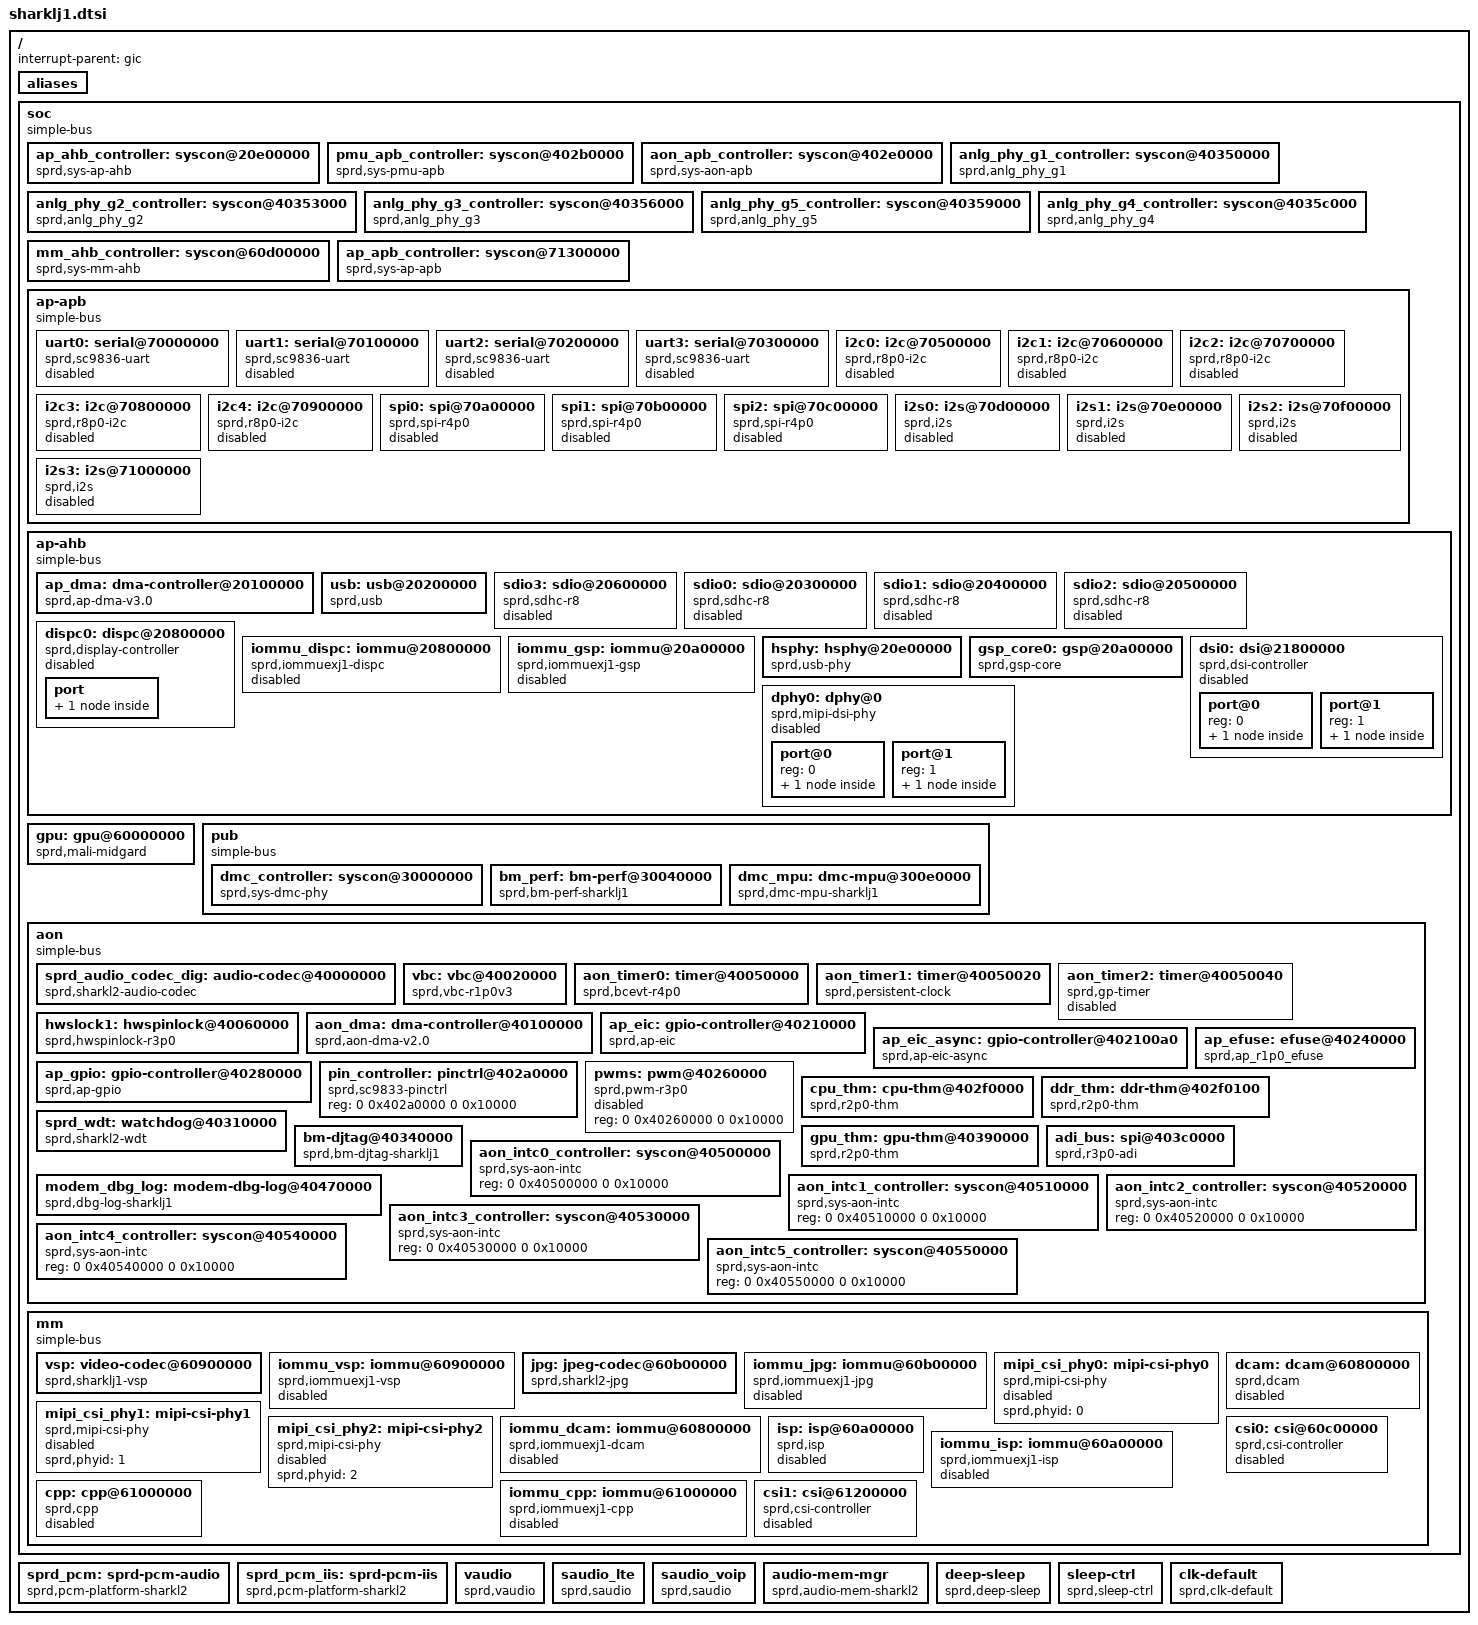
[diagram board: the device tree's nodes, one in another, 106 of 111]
/*
 * Spreadtrum Sharklj1 platform DTS file
 *
 * Copyright (C) 2016, Spreadtrum Communications Inc.
 *
 * This file is licensed under a dual GPLv2 or X11 license.
 */

#include <dt-bindings/interrupt-controller/arm-gic.h>

/ {
	interrupt-parent = <&gic>;
	#address-cells = <2>;
	#size-cells = <2>;

	aliases {
		serial0 = &uart0;
		serial1 = &uart1;
		serial2 = &uart2;
		serial3 = &uart3;
		i2c0 = &i2c0;
		i2c1 = &i2c1;
		i2c2 = &i2c2;
		i2c3 = &i2c3;
		i2c4 = &i2c4;
		spi0 = &spi0;
		spi1 = &spi1;
		spi2 = &spi2;
		hwspinlock1 = &hwslock1;
		thm-sensor0 = &cpu_thm;
		thm-sensor1 = &ddr_thm;
		thm-sensor2 = &gpu_thm;
	};

	soc: soc {
		compatible = "simple-bus";
		#address-cells = <2>;
		#size-cells = <2>;
		ranges;

		ap_ahb_controller: syscon@20e00000 {
			compatible = "sprd,sys-ap-ahb", "syscon";
			reg = <0 0x20e00000 0 0x100000>;
			hwlocks = <&hwslock1 1>;
			hwlock-names = "syscon";
		};

		pmu_apb_controller: syscon@402b0000 {
			compatible = "sprd,sys-pmu-apb", "syscon";
			reg = <0 0x402b0000 0 0x10000>;
			hwlocks = <&hwslock1 1>;
			hwlock-names = "syscon";
		};

		aon_apb_controller: syscon@402e0000 {
			compatible = "sprd,sys-aon-apb", "syscon";
			reg = <0 0x402e0000 0 0x10000>;
			hwlocks = <&hwslock1 1>;
			hwlock-names = "syscon";
		};

		anlg_phy_g1_controller: syscon@40350000 {
			compatible = "sprd,anlg_phy_g1", "syscon";
			reg = <0 0x40350000 0 0x3000>;
			hwlocks = <&hwslock1 1>;
			hwlock-names = "syscon";
		};

		anlg_phy_g2_controller: syscon@40353000 {
			compatible = "sprd,anlg_phy_g2", "syscon";
			reg = <0 0x40353000 0 0x3000>;
			hwlocks = <&hwslock1 1>;
			hwlock-names = "syscon";
		};

		anlg_phy_g3_controller: syscon@40356000 {
			compatible = "sprd,anlg_phy_g3", "syscon";
			reg = <0 0x40356000 0 0x3000>;
			hwlocks = <&hwslock1 1>;
			hwlock-names = "syscon";
		};

		anlg_phy_g5_controller: syscon@40359000 {
			compatible = "sprd,anlg_phy_g5", "syscon";
			reg = <0 0x40359000 0 0x3000>;
			hwlocks = <&hwslock1 1>;
			hwlock-names = "syscon";
		};

		anlg_phy_g4_controller: syscon@4035c000 {
			compatible = "sprd,anlg_phy_g4", "syscon";
			reg = <0 0x4035c000 0 0x3000>;
			hwlocks = <&hwslock1 1>;
			hwlock-names = "syscon";
		};

		mm_ahb_controller: syscon@60d00000 {
			compatible = "sprd,sys-mm-ahb", "syscon";
			reg = <0 0x60d00000 0 0x100000>;
			hwlocks = <&hwslock1 1>;
			hwlock-names = "syscon";
		};

		ap_apb_controller: syscon@71300000 {
			compatible = "sprd,sys-ap-apb", "syscon";
			reg = <0 0x71300000 0 0x100000>;
			hwlocks = <&hwslock1 1>;
			hwlock-names = "syscon";
		};

		ap-apb {
			compatible = "simple-bus";
			#address-cells = <2>;
			#size-cells = <2>;
			ranges;

			uart0: serial@70000000 {
				compatible = "sprd,sc9836-uart",
					     "sprd,sc9838-uart";
				reg = <0 0x70000000 0 0x100>;
				interrupts = <GIC_SPI 2 IRQ_TYPE_LEVEL_HIGH>;
				clock-names = "uart", "source","enable";
				status = "disabled";
			};

			uart1: serial@70100000 {
				compatible = "sprd,sc9836-uart",
					     "sprd,sc9838-uart";
				reg = <0 0x70100000 0 0x100>;
				interrupts = <GIC_SPI 3 IRQ_TYPE_LEVEL_HIGH>;
				clock-names = "uart", "source","enable";
				status = "disabled";
			};

			uart2: serial@70200000 {
				compatible = "sprd,sc9836-uart",
					     "sprd,sc9838-uart";
				reg = <0 0x70200000 0 0x100>;
				interrupts = <GIC_SPI 4 IRQ_TYPE_LEVEL_HIGH>;
				clock-names = "uart", "source","enable";
				status = "disabled";
			};

			uart3: serial@70300000 {
				compatible = "sprd,sc9836-uart",
					     "sprd,sc9838-uart";
				reg = <0 0x70300000 0 0x100>;
				interrupts = <GIC_SPI 5 IRQ_TYPE_LEVEL_HIGH>;
				clock-names = "uart", "source","enable";
				status = "disabled";
			};

			i2c0: i2c@70500000 {
				compatible = "sprd,r8p0-i2c";
				reg = <0 0x70500000 0 0x1000>;
				interrupts = <GIC_SPI 11 IRQ_TYPE_LEVEL_HIGH>;
				clock-names = "i2c", "source","enable";
				clock-frequency = <100000>;
				#address-cells = <1>;
				#size-cells = <0>;
				status = "disabled";
			};

			i2c1: i2c@70600000 {
				compatible = "sprd,r8p0-i2c";
				reg = <0 0x70600000 0 0x1000>;
				interrupts = <GIC_SPI 12 IRQ_TYPE_LEVEL_HIGH>;
				clock-names = "i2c", "source","enable";
				clock-frequency = <100000>;
				#address-cells = <1>;
				#size-cells = <0>;
				status = "disabled";
			};

			i2c2: i2c@70700000 {
				compatible = "sprd,r8p0-i2c";
				reg = <0 0x70700000 0 0x1000>;
				interrupts = <GIC_SPI 13 IRQ_TYPE_LEVEL_HIGH>;
				clock-names = "i2c", "source","enable";
				clock-frequency = <100000>;
				#address-cells = <1>;
				#size-cells = <0>;
				status = "disabled";
			};

			i2c3: i2c@70800000 {
				compatible = "sprd,r8p0-i2c";
				reg = <0 0x70800000 0 0x1000>;
				interrupts = <GIC_SPI 14 IRQ_TYPE_LEVEL_HIGH>;
				clock-names = "i2c", "source","enable";
				clock-frequency = <400000>;
				#address-cells = <1>;
				#size-cells = <0>;
				status = "disabled";
			};

			i2c4: i2c@70900000 {
				compatible = "sprd,r8p0-i2c";
				reg = <0 0x70900000 0 0x1000>;
				interrupts = <GIC_SPI 15 IRQ_TYPE_LEVEL_HIGH>;
				clock-names = "i2c", "source","enable";
				clock-frequency = <100000>;
				#address-cells = <1>;
				#size-cells = <0>;
				status = "disabled";
			};

			spi0: spi@70a00000{
				compatible = "sprd,spi-r4p0";
				reg = <0 0x70a00000 0 0x1000>;
				interrupts = <GIC_SPI 7 IRQ_TYPE_LEVEL_HIGH>;
				clock-names = "spi", "source","enable";
				sprd,dma-mode = <0>;
				sprd,rxtx-dma = <11 12>;
				dma-names = "rx_chn", "tx_chn";
				dmas = <&ap_dma 11 &ap_dma 12>;
				#address-cells = <1>;
				#size-cells = <0>;
				status = "disabled";
			};

			spi1: spi@70b00000{
				compatible = "sprd,spi-r4p0";
				reg = <0 0x70b00000 0 0x1000>;
				interrupts = <GIC_SPI 8 IRQ_TYPE_LEVEL_HIGH>;
				clock-names = "spi", "source", "enable";
				sprd,dma-mode = <0>;
				sprd,rxtx-dma = <13 14>;
				dma-names = "rx_chn", "tx_chn";
				dmas = <&ap_dma 13 &ap_dma 14>;
				#address-cells = <1>;
				#size-cells = <0>;
				status = "disabled";
			};

			spi2: spi@70c00000{
				compatible = "sprd,spi-r4p0";
				reg = <0 0x70c00000 0 0x1000>;
				interrupts = <GIC_SPI 9 IRQ_TYPE_LEVEL_HIGH>;
				clock-names = "spi", "source","enable";
				sprd,dma-mode = <0>;
				sprd,rxtx-dma = <15 16>;
				dma-names = "rx_chn", "tx_chn";
				dmas = <&ap_dma 15 &ap_dma 16>;
				#address-cells = <1>;
				#size-cells = <0>;
				status = "disabled";
			};

			i2s0: i2s@70d00000 {
				compatible = "sprd,i2s";
				reg = <0 0x70d00000 0 0x100000>;
				sprd,dai_name = "i2s_bt_sco0";
				sprd,hw_port = <0>;
				sprd,syscon-ap-apb = <&ap_apb_controller>;
				#sound-dai-cells = <0>;
				status = "disable";
			};

			i2s1: i2s@70e00000 {
				compatible = "sprd,i2s";
				reg = <0 0x70e00000 0 0x100000>;
				sprd,dai_name = "i2s_bt_sco1";
				sprd,hw_port = <1>;
				sprd,syscon-ap-apb = <&ap_apb_controller>;
				#sound-dai-cells = <0>;
				status = "disable";
			};

			i2s2: i2s@70f00000 {
				compatible = "sprd,i2s";
				reg = <0 0x70f00000 0 0x100000>;
				sprd,dai_name = "i2s_bt_sco2";
				sprd,hw_port = <2>;
				sprd,syscon-ap-apb = <&ap_apb_controller>;
				#sound-dai-cells = <0>;
				status = "disable";
			};

			i2s3: i2s@71000000 {
				compatible = "sprd,i2s";
				reg = <0 0x71000000 0 0x100000>;
				sprd,dai_name = "i2s_bt_sco3";
				sprd,hw_port = <3>;
				sprd,syscon-ap-apb = <&ap_apb_controller>;
				#sound-dai-cells = <0>;
				status = "disable";
			};
		};

		ap-ahb {
			compatible = "simple-bus";
			#address-cells = <2>;
			#size-cells = <2>;
			ranges;

			ap_dma: dma-controller@20100000 {
				compatible = "sprd,ap-dma-v3.0";
				reg = <0 0x20100000 0 0x4000>;
				interrupts = <GIC_SPI 50 IRQ_TYPE_LEVEL_HIGH>;
				#dma-cells = <1>;
				#dma-channels = <28>;
				sprd,full-type-offset = <0>;
				sprd,syscon-dma-glb = <&ap_ahb_controller>;
				clock-names = "enable";
				clocks = <&clk_ap_ahb_gates 5>;
			};

			usb: usb@20200000 {
				compatible  = "sprd,usb";
				reg = <0 0x20200000 0 0x2000>;
				interrupts = <GIC_SPI 55 IRQ_TYPE_LEVEL_HIGH>;
				interrupt-names = "mc";
				clocks = <&clk_ap_ahb_gates 4>;
				clock-names = "core_clk";
				phy-type = "usb20_sprd_phy";
				usb-phy = <&hsphy>;
				phy-names = "usb";
				dr-mode = "peripheral";
			};

			sdio3: sdio@20600000 {
				compatible  = "sprd,sdhc-r8";
				reg = <0 0x20600000 0 0x1000>;
				interrupts = <GIC_SPI 60 IRQ_TYPE_LEVEL_HIGH>;
				clock-names = "sdio","source","enable",
					"ckg_eb","ckg_1x_eb";
				clocks = <&clk_emmc_2x>,<&clk_rpll_390m>,
					<&clk_ap_ahb_gates 11>,
					<&clk_aon_eb0_gates 1>,
					<&clk_aon_eb0_gates 0>;
				status = "disabled";
			};

			sdio0: sdio@20300000 {
				compatible  = "sprd,sdhc-r8";
				reg = <0 0x20300000 0 0x1000>;
				interrupts = <GIC_SPI 57 IRQ_TYPE_LEVEL_HIGH>;
				clock-names = "sdio","source","enable",
					"ckg_eb","ckg_1x_eb";
				clocks = <&clk_sdio0_2x>,<&clk_rpll_390m>,
					<&clk_ap_ahb_gates 8>,
					<&clk_aon_eb0_gates 3>,
					<&clk_aon_eb0_gates 2>;
				status = "disabled";
			};

			sdio1: sdio@20400000 {
				compatible  = "sprd,sdhc-r8";
				reg = <0 0x20400000 0 0x1000>;
				interrupts = <GIC_SPI 58 IRQ_TYPE_LEVEL_HIGH>;
				clock-names = "sdio", "source","enable",
					"ckg_eb","ckg_1x_eb";
				clocks = <&clk_sdio1_2x>,<&clk_rpll_390m>,
					<&clk_ap_ahb_gates 9>,
					<&clk_aon_eb0_gates 5>,
					<&clk_aon_eb0_gates 4>;
				status = "disabled";
			};

			sdio2: sdio@20500000 {
				compatible  = "sprd,sdhc-r8";
				reg = <0 0x20500000 0 0x1000>;
				interrupts = <GIC_SPI 59 IRQ_TYPE_LEVEL_HIGH>;
				clock-names = "sdio","source","enable",
					"ckg_eb","ckg_1x_eb";
				clocks = <&clk_sdio2_2x>,<&clk_rpll_390m>,
					<&clk_ap_ahb_gates 10>,
					<&clk_aon_eb0_gates 7>,
					<&clk_aon_eb0_gates 6>;
				status = "disabled";
			};


			dispc0: dispc@20800000 {
				compatible = "sprd,display-controller";
				reg = <0x0 0x20800000 0x0 0x1000>;
				dev-id = <0>;
				sprd,dpi_clk_div = <1>;
				interrupts = <GIC_SPI 46 IRQ_TYPE_LEVEL_HIGH>;
				clock-src = <384000000 128000000>;
				clock-names =   "clk_dispc_core_parent",
						"clk_dispc_dpi_parent",
						"clk_dispc_core",
						"clk_dispc_dpi",
						"clk_dispc_ahb_eb";

				clocks =	<&clk_twpll_384m>,
						<&clk_twpll_128m>,
						<&clk_dispc0>,
						<&clk_dispc0_dpi>,
						<&clk_ap_ahb_gates 1>;
				iommus = <&iommu_dispc>;
				status = "disabled";

				sprd,ip = "dispc-lite-r2p0";
				sprd,soc = "sharklj1";

				/* output port */
				port {
					dispc0_out: endpoint@0 {
						remote-endpoint = <&dsi0_in>;
					};
				};
			};

			iommu_dispc: iommu@20800000 {
				compatible = "sprd,iommuexj1-dispc";
				reg = <0x0 0x20800000 0x0 0x800>,
					<0x0 0x20800800 0x0 0x60>,
					<0x0 0x30000000 0x0 0x8000000>;
				reg_name = "mmu_interrupt_reg","mmu_reg",
						"iova pool";
				status = "disabled";
				#iommu-cells = <0>;
			};

			iommu_gsp: iommu@20a00000 {
				compatible = "sprd,iommuexj1-gsp";
				reg = <0x0 0x20a00000 0x0 0x804>,
					<0x0 0x20a00804 0x0 0x60>,
					<0x0 0x20000000 0x0 0x10000000>;
				reg_name = "mmu_interrupt_reg","mmu_reg",
						"iova pool";
				status = "disabled";
				#iommu-cells = <0>;
			};

			hsphy: hsphy@20e00000 {
				compatible = "sprd,usb-phy";
				sprd,syscon-enable = <&aon_apb_controller>;
				sprd,syscon-apahb = <&ap_ahb_controller>;
				sprd,syscon-anag2 = <&anlg_phy_g2_controller>;
				sprd,tune-value = <0x0c373b9d>;
				sprd,vdd-voltage = <3300000>;
				#phy-cells = <0>;
			};

			gsp_core0: gsp@20a00000 {
				compatible = "sprd,gsp-core";
				reg = <0 0x20a00000  0 0x1000>;
				core-id = <0>;
				kcfg-num = <8>;
				interrupts = <GIC_SPI 51 IRQ_TYPE_LEVEL_HIGH>;
				iommus = <&iommu_gsp>;
				sprd,sys-ap-ahb = <&ap_ahb_controller>;
				clock-names = "clk_gsp",
						 "clk_gsp_parent",
						 "clk_gsp_eb";
				clocks = <&clk_gsp>,
						 <&clk_twpll_307m2>,
						 <&clk_ap_ahb_gates 3>;
			};

			dsi0: dsi@21800000 {
				compatible = "sprd,dsi-controller";
				#address-cells = <1>;
				#size-cells = <0>;
				dev-id = <0>;
				reg = <0x0 0x21800000 0x0 0x1000>;
				interrupts = <GIC_SPI 48 IRQ_TYPE_LEVEL_HIGH>,
					<GIC_SPI 49 IRQ_TYPE_LEVEL_HIGH>;
				clock-names =   "clk_dsi0_ahb_eb";
				clocks = <&clk_ap_ahb_gates 0>;
				status = "disabled";

				sprd,ip = "sprd,dsi-ctrl-r1p0";
				sprd,soc = "sharklj1";

				/* output port */
				port@0 {
					reg = <0>;
					dsi0_out: endpoint {
						remote-endpoint = <&dphy0_in>;
					};
				};

				/* input port */
				port@1 {
					reg = <1>;
					dsi0_in: endpoint {
						remote-endpoint = <&dispc0_out>;
					};
				};
			};

			dphy0: dphy@0 {
				compatible = "sprd,mipi-dsi-phy";
				#address-cells = <1>;
				#size-cells = <0>;
				reg = <0x0 0x21800000 0x0 0x1000>;
				status = "disabled";

				sprd,ip = "sprd,megacores-sharkle";
				sprd,soc = "sharklj1";

				/* output port */
				port@0 {
					reg = <0>;
					dphy0_out: endpoint {
						remote-endpoint = <&panel_in>;
					};
				};

				/* input port*/
				port@1 {
					reg = <1>;
					dphy0_in: endpoint {
						remote-endpoint = <&dsi0_out>;
					};
				};
			};
		};

		gpu: gpu@60000000 {
			compatible = "sprd,mali-midgard";
			reg = <0 0x60000000 0 0x4000>;
			sprd,syscon-aon-apb = <&aon_apb_controller>;
			sprd,syscon-pmu-apb = <&pmu_apb_controller>;
			interrupts = <GIC_SPI 39 IRQ_TYPE_LEVEL_HIGH>,
				<GIC_SPI 39 IRQ_TYPE_LEVEL_HIGH>,
				<GIC_SPI 39 IRQ_TYPE_LEVEL_HIGH>;
			interrupt-names = "JOB",
				"MMU",
				"GPU";

			system-coherency = <31>;

			clocks = <&clk_aon_apb_gates0 27>,<&clk_gpu>,
				<&clk_twpll_153m6>,<&clk_twpll_192m>,
				<&clk_twpll_256m>,<&clk_twpll_307m2>,
				<&clk_twpll_384m>,<&clk_twpll_512m>,
				<&clk_gpll>;

			operating-points = <
				/* kHz    uV */
				153600    0
				256000    0
				384000    0
				512000    0
				700000    0
				>;

			sprd,dfs-lists = <
				/* kHz  uV idx div */
				153600  0   2   1
				256000  0   4   1
				384000  0   6   1
				512000  0   7   1
				700000  0   8   1
				>;

			sprd,dfs-default = <1>;
			sprd,dfs-scene-extreme = <3>;
			sprd,dfs-scene-high = <2>;
			sprd,dfs-scene-medium = <1>;
			sprd,dfs-scene-low = <0>;
			sprd,dfs-range-max = <4>;
			sprd,dfs-range-min = <0>;
		};

		pub {
			compatible = "simple-bus";
			#address-cells = <2>;
			#size-cells = <2>;
			ranges;

			dmc_controller: syscon@30000000 {
				compatible = "sprd,sys-dmc-phy", "syscon";
				reg = <0 0x30000000 0 0x400>;
				sprd,sizel_off = <0x1b4>;
				sprd,sizeh_off = <0x1b8>;
			};

			bm_perf: bm-perf@30040000{
				compatible = "sprd,bm-perf-sharklj1";
				reg = <0 0x30040000 0 0x80000>,
					<0 0 0 0>,
					<0 0x40270000 0 0x10000>,
					<0 0x300e0000 0 0x4>,
					<0 0 0 0>;
				interrupts = <GIC_SPI 86 IRQ_TYPE_LEVEL_HIGH>;
				reg-names = "pub0","pub1","timer",
						"pub0_glb","pub1_glb";
				sprd,syscon-aon-glb = <&aon_apb_controller>;
			};

			dmc_mpu: dmc-mpu@300e0000{
				compatible = "sprd,dmc-mpu-sharklj1";
				reg = <0 0x300e0000 0 0x4000>;
				interrupts = <GIC_SPI 61 IRQ_TYPE_LEVEL_HIGH>;
			};
		};

		aon {
			compatible = "simple-bus";
			#address-cells = <2>;
			#size-cells = <2>;
			ranges;

			sprd_audio_codec_dig: audio-codec@40000000 {
				compatible = "sprd,sharkl2-audio-codec";
				reg = <0 0x40000000 0 0x2000>;
				sprd,def_da_fs = <44100>;
				interrupts = <GIC_SPI 20  IRQ_TYPE_NONE>;
				sprd,syscon-aon-apb = <&aon_apb_controller>;
				/* sharklj1 use g1 */
				sprd,anlg-phy-g-syscon = <&anlg_phy_g1_controller>;
			};

			vbc: vbc@40020000 {
				compatible = "sprd,vbc-r1p0v3";
				#sound-dai-cells = <1>;
				reg = <0 0x40020000 0 0x10000>;
				sprd,clk-stable = <0x402d0060 0x4>;
				sprd,syscon-aon-apb = <&aon_apb_controller>;
				sprd,syscon-pmu-apb = <&pmu_apb_controller>;
				sprd,dynamic-eq-support = <0>;
				/* da01, ad01, ad23 */
				sprd,vbc-iis-lr-invert = <0 0 1>;
				/*
				 * 0: aon dma, 1: ap dma
				 * da01, da23, ad01, ad23
				 */
				sprd,vbc-use-dma-type = <0 0 1 1>;
				sprd,vbc-use-ad01-only = <0>;
				/* iis pin map */
				pinctrl-names =
				/* iis 0 */
				"ap_iis0_0", "pubcp_iis0_0", "tgdsp_iis0_0",
				"vbc_iis1_0", "vbc_iis2_0", "vbc_iis3_0",
				/* iis 2 */
				"ap_iis0_2", "pubcp_iis0_2", "tgdsp_iis0_2",
				"vbc_iis1_2", "vbc_iis2_2", "vbc_iis3_2";

				/* sys iis 0 */
				pinctrl-0 = <&ap_iis0_0>;
				pinctrl-1 = <&pubcp_iis0_0>;
				pinctrl-2 = <&tgdsp_iis0_0>;
				pinctrl-3 = <&vbc_iis1_0>;
				pinctrl-4 = <&vbc_iis2_0>;
				pinctrl-5 = <&vbc_iis3_0>;
				/* sys iis 2 */
				pinctrl-6 = <&ap_iis0_2>;
				pinctrl-7 = <&pubcp_iis0_2>;
				pinctrl-8 = <&tgdsp_iis0_2>;
				pinctrl-9 = <&vbc_iis1_2>;
				pinctrl-10 = <&vbc_iis2_2>;
				pinctrl-11 = <&vbc_iis3_2>;
			};

			aon_timer0: timer@40050000 {
				compatible = "sprd,bcevt-r4p0";
				reg = <0 0x40050000 0 0x14>;
				interrupts = <GIC_SPI 28 IRQ_TYPE_LEVEL_HIGH>;
				clock-frequency = <32768>;
			};

			aon_timer1: timer@40050020 {
				compatible = "sprd,persistent-clock";
				reg = <0 0x40050020 0 0x14>;
				interrupts = <GIC_SPI 28 IRQ_TYPE_LEVEL_HIGH>;
				clock-frequency = <32768>;
			};

			aon_timer2: timer@40050040 {
				compatible = "sprd,gp-timer";
				reg = <0 0x40050040 0 0x14>;
				clock-frequency = <26000000>;
				status = "disabled";
			};

			hwslock1: hwspinlock@40060000{
				compatible  = "sprd,hwspinlock-r3p0";
				reg = <0 0x40060000 0 0x1000>;
				#hwlock-cells = <1>;
				hwlocks-base = <0>;
				hwlocks-num = <32>;
				clock-names = "enable";
				sprd,axi-id;
			};

			aon_dma: dma-controller@40100000 {
				compatible = "sprd,aon-dma-v2.0";
				reg = <0x0 0x40100000 0x0 0x4000>;
				#dma-cells = <1>;
				#dma-channels = <12>;
				sprd,full-type-offset = <0>;
				sprd,syscon-dma-glb = <&aon_apb_controller>;
				clock-names = "enable";
				clocks = <&clk_aon_apb_gates1 22>;
			};

			ap_eic: gpio-controller@40210000 {
				compatible = "sprd,ap-eic";
				reg =	<0x0 0x40210000 0x0 0x80>,
					<0x0 0x40370000 0x0 0x80>;
				gpio-controller;
				#gpio-cells = <2>;
				sprd,gpiobase = <288>;
				sprd,ngpios = <32>;
				interrupt-controller;
				#interrupt-cells = <2>;
				interrupts = <GIC_SPI 37 IRQ_TYPE_LEVEL_HIGH>;
			};

			ap_eic_async: gpio-controller@402100a0 {
				compatible = "sprd,ap-eic-async";
				reg =	<0x0 0x402100a0 0x0 0x40>,
					<0x0 0x403700a0 0x0 0x40>;
				gpio-controller;
				#gpio-cells = <2>;
				sprd,gpiobase = <336>;
				sprd,ngpios = <32>;
				interrupt-controller;
				#interrupt-cells = <2>;
				interrupts = <GIC_SPI 37 IRQ_TYPE_LEVEL_HIGH>;
			};

			ap_efuse: efuse@40240000 {
				compatible = "sprd,ap_r1p0_efuse";
				sprd,syscon-enable = <&aon_apb_controller>;
				reg = <0 0x40240000 0 0x1000>;
				clock-names = "enable";
				clocks = <&clk_aon_apb_gates0 13>;
				sprd,block-num = <16>;
				sprd,block-width = <32>;
				hwlocks = <&hwslock1 8>;
				hwlock-names = "ap_efuse";
			};

			ap_gpio: gpio-controller@40280000 {
				compatible = "sprd,ap-gpio";
				reg = <0x0 0x40280000 0x0 0x1000>;
				gpio-controller;
				#gpio-cells = <2>;
				sprd,gpiobase = <0>;
				sprd,ngpios = <256>;
				interrupt-controller;
				#interrupt-cells = <2>;
				interrupts = <GIC_SPI 35 IRQ_TYPE_LEVEL_HIGH>;
			};

			pin_controller: pinctrl@402a0000 {
				compatible = "sprd,sc9833-pinctrl";
				reg = <0 0x402a0000 0 0x10000>;
			};

			pwms: pwm@40260000 {
				#pwm-cells = <2>;
				compatible = "sprd,pwm-r3p0";
				reg = <0 0x40260000 0 0x10000>;
				status = "disabled";
			};

			cpu_thm: cpu-thm@402f0000 {
				compatible = "sprd,r2p0-thm";
				sprd,syscon-enable = <&aon_apb_controller>;
				reg = <0 0x402f0000 0 0x100>;
				clock-names = "enable";
				clocks = <&clk_aon_apb_gates1 1>;
				#thermal-sensor-cells = <1>;
				power-down = <0>;
				otp-temp = <120000>;
				algor_ver = <1>;
				cal_k = <903>;
				cal_b = <71290>;
				cal_efuse_blk = <8>;
				cal_efuse_bit = <9>;
				ratio_off_bit = <2>;
				ratio_sign_bit = <1>;
			};

			ddr_thm: ddr-thm@402f0100 {
				compatible = "sprd,r2p0-thm";
				sprd,syscon-enable = <&aon_apb_controller>;
				reg = <0 0x402f0100 0 0x100>;
				clock-names = "enable";
				clocks = <&clk_aon_apb_gates1 1>;
				#thermal-sensor-cells = <1>;
				power-down = <0>;
				otp-temp = <120000>;
				algor_ver = <1>;
				cal_k = <903>;
				cal_b = <71290>;
				cal_efuse_blk = <8>;
				cal_efuse_bit = <24>;
				ratio_off_bit = <17>;
				ratio_sign_bit = <16>;
			};

			sprd_wdt: watchdog@40310000 {
				compatible = "sprd,sharkl2-wdt";
				reg = <0 0x40310000 0 0x1000>;
				interrupts = <GIC_SPI 124 IRQ_TYPE_LEVEL_HIGH>;
				clock-names = "enable", "rtc_enable";
				sprd,wdt-enable = <&aon_apb_controller>;
			};

			bm-djtag@40340000 {
				compatible = "sprd,bm-djtag-sharklj1";
				reg = <0 0x40340000 0 0x10000>;
				interrupts = <GIC_SPI 67 IRQ_TYPE_LEVEL_HIGH>;
				sprd,syscon-aon-glb = <&aon_apb_controller>;
				sprd,syscon-ap-glb = <&ap_ahb_controller>;
				hwlocks = <&hwslock1 10>;
				hwlock-names = "djtag";
			};

			gpu_thm: gpu-thm@40390000 {
				compatible = "sprd,r2p0-thm";
				sprd,syscon-enable = <&aon_apb_controller>;
				reg = <0 0x40390000 0 0x100>;
				clock-names = "enable";
				clocks = <&clk_aon_apb_gates1 1>;
				#thermal-sensor-cells = <1>;
				power-down = <0>;
				otp-temp = <120000>;
				algor_ver = <1>;
				cal_k = <903>;
				cal_b = <71290>;
				cal_efuse_blk = <9>;
				cal_efuse_bit = <9>;
				ratio_off_bit = <2>;
				ratio_sign_bit = <1>;
			};

			adi_bus: spi@403c0000 {
				compatible = "sprd,r3p0-adi";
				reg = <0 0x403c0000 0 0x10000>;
				#address-cells = <1>;
				#size-cells = <0>;
				sprd,hw-channels = <33 0x8c20>;
			};

			modem_dbg_log: modem-dbg-log@40470000 {
				compatible = "sprd,dbg-log-sharklj1";
				reg = <0 0x40470000 0 0x1000>,
				<0 0x404a0000 0 0x1000>;
				sprd,syscon-aon-apb = <&aon_apb_controller>;
			};

			aon_intc0_controller: syscon@40500000 {
				compatible = "sprd,sys-aon-intc", "syscon";
				reg = <0 0x40500000 0 0x10000>;
			};

			aon_intc1_controller: syscon@40510000 {
				compatible = "sprd,sys-aon-intc", "syscon";
				reg = <0 0x40510000 0 0x10000>;
			};

			aon_intc2_controller: syscon@40520000 {
				compatible = "sprd,sys-aon-intc", "syscon";
				reg = <0 0x40520000 0 0x10000>;
			};

			aon_intc3_controller: syscon@40530000 {
				compatible = "sprd,sys-aon-intc", "syscon";
				reg = <0 0x40530000 0 0x10000>;
			};

			aon_intc4_controller: syscon@40540000 {
				compatible = "sprd,sys-aon-intc", "syscon";
				reg = <0 0x40540000 0 0x10000>;
			};

			aon_intc5_controller: syscon@40550000 {
				compatible = "sprd,sys-aon-intc", "syscon";
				reg = <0 0x40550000 0 0x10000>;
			};
		};

		mm {
			compatible = "simple-bus";
			#address-cells = <2>;
			#size-cells = <2>;
			ranges;

			vsp: video-codec@60900000{
				compatible = "sprd,sharklj1-vsp";
				reg = <0 0x60900000 0 0xc000>;
				interrupts = <GIC_SPI 43 IRQ_TYPE_LEVEL_HIGH>;
				sprd,syscon-pmu-apb = <&pmu_apb_controller>;
				sprd,syscon-aon-apb = <&aon_apb_controller>;
				sprd,syscon-mm-ahb = <&mm_ahb_controller>;
				iommus = <&iommu_vsp>;
				status = "ok";
			};

			iommu_vsp: iommu@60900000 {
				compatible = "sprd,iommuexj1-vsp";
				reg = <0 0x60900000 0 0x1140>,
				<0 0x60901140 0 0x60>,
				<0 0x10000000 0 0x10000000>;
				reg_name = "mmu_interrupt_reg","mmu_reg",
						"iova pool";
				status = "disabled";
				#iommu-cells = <0>;
			};


			jpg: jpeg-codec@60b00000{
				compatible = "sprd,sharkl2-jpg";
				reg = <0 0x60b00000 0 0x8000>;
				interrupts = <GIC_SPI 42 IRQ_TYPE_LEVEL_HIGH>;
				sprd,syscon-pmu-apb = <&pmu_apb_controller>;
				sprd,syscon-aon-apb = <&aon_apb_controller>;
				sprd,syscon-mm-ahb = <&mm_ahb_controller>;
				iommus = <&iommu_jpg>;
				status = "okay";
			};

			iommu_jpg: iommu@60b00000 {
				compatible = "sprd,iommuexj1-jpg";
				reg = <0 0x60b00000 0 0x100>,
				<0 0x60b00100 0 0x400>,
				<0 0x70000000 0 0x10000000>;
				reg_name = "mmu_interrupt_reg","mmu_reg",
						"iova pool";
				status = "disabled";
				#iommu-cells = <0>;
			};

			mipi_csi_phy0: mipi-csi-phy0 {
				compatible = "sprd,mipi-csi-phy";
				sprd,phyid = <0>;
				status = "disabled";
			};

			mipi_csi_phy1: mipi-csi-phy1 {
				compatible = "sprd,mipi-csi-phy";
				sprd,phyid = <1>;
				status = "disabled";
			};

			mipi_csi_phy2: mipi-csi-phy2 {
				compatible = "sprd,mipi-csi-phy";
				sprd,phyid = <2>;
				status = "disabled";
			};

			dcam: dcam@60800000 {
				compatible = "sprd,dcam";
				reg = <0 0x60800000 0 0x1000>;
				interrupts = <GIC_SPI 45 IRQ_TYPE_LEVEL_HIGH>;
				sprd,cam-ahb-syscon = <&mm_ahb_controller>;
				sprd,aon-apb-syscon = <&aon_apb_controller>;
				sprd,syscon-pmu-apb = <&pmu_apb_controller>;
				sprd,isp = <&isp>;
				sprd,dcam-count = <1>;
				iommus = <&iommu_dcam>;
				status = "disable";
			};

			iommu_dcam: iommu@60800000 {
				compatible = "sprd,iommuexj1-dcam";
				reg = <0 0x60800000 0 0x80>,
				<0 0x60800080 0 0x60>,
				<0 0x40000000 0 0x4000000>;
				reg_name = "mmu_interrupt_reg","mmu_reg",
						"iova pool";
				status = "disabled";
				#iommu-cells = <0>;
			};

			isp: isp@60a00000 {
				compatible = "sprd,isp";
				reg = <0 0x60a00000 0 0x100000>;
				interrupts = <GIC_SPI 44 IRQ_TYPE_LEVEL_HIGH>,
				<GIC_SPI 125 IRQ_TYPE_LEVEL_HIGH>;
				sprd,cam-ahb-syscon = <&mm_ahb_controller>;
				sprd,aon-apb-syscon = <&aon_apb_controller>;
				sprd,isp-count = <1>;
				iommus = <&iommu_isp>;
				status = "disable";
			};

			iommu_isp: iommu@60a00000 {
				compatible = "sprd,iommuexj1-isp";
				/*sharkl2 isp need pagetalbe size*/
				reg = <0 0x60a00000 0 0x800>,
				<0 0x60a00800 0 0x400>,
				<0 0x50000000 0 0x10000000>;
				reg_name = "mmu_interrupt_reg","mmu_reg",
						"iova pool";
				status = "disabled";
				#iommu-cells = <0>;
			};

			csi0: csi@60c00000 {
				compatible = "sprd,csi-controller";
				reg = <0 0x60c00000 0 0x1000>;
				interrupts = <GIC_SPI 40 IRQ_TYPE_LEVEL_HIGH>,
					<GIC_SPI 41 IRQ_TYPE_LEVEL_HIGH>;
				sprd,cam-ahb-syscon = <&mm_ahb_controller>;
				sprd,ana-apb-syscon = <&aon_apb_controller>;
				sprd,csi-id = <0>;
				sprd,ip-version = <0x100>;
				status = "disable";
			};

			cpp: cpp@61000000 {
				compatible = "sprd,cpp";
				reg = <0 0x61000000 0 0x1000>;
				interrupts = <GIC_SPI 126 IRQ_TYPE_LEVEL_HIGH>;
				sprd,cam-ahb-syscon = <&mm_ahb_controller>;
				sprd,ana-apb-syscon = <&aon_apb_controller>;
				iommus = <&iommu_cpp>;
				status = "disable";
			};

			iommu_cpp: iommu@61000000 {
				compatible = "sprd,iommuexj1-cpp";
				reg = <0 0x61000000 0 0x200>,
				<0 0x61000200 0 0x60>,
				<0 0x60000000 0 0x8000000>;
				reg_name = "mmu_interrupt_reg","mmu_reg",
						"iova pool";
				status = "disabled";
				#iommu-cells = <0>;
			};

			csi1: csi@61200000 {
				compatible = "sprd,csi-controller";
				reg = <0 0x61200000 0 0x1000>;
				interrupts = <GIC_SPI 71 IRQ_TYPE_LEVEL_HIGH>,
					<GIC_SPI 72 IRQ_TYPE_LEVEL_HIGH>;
				sprd,cam-ahb-syscon = <&mm_ahb_controller>;
				sprd,ana-apb-syscon = <&aon_apb_controller>;
				sprd,csi-id = <1>;
				sprd,ip-version = <0x100>;
				status = "disable";
			};
		};
	};

	sprd_pcm: sprd-pcm-audio {
		compatible = "sprd,pcm-platform-sharkl2";
		#sound-dai-cells = <0>;
		/* non-i2s playbacks use aon dma */
		/*
		 * reference dma node dma-channels proporty
		 * do not conflict with others
		 * ap_dma (29-32 for security)
		 */
		dmas = <&aon_dma 1 &aon_dma 2
			&aon_dma 3 &aon_dma 4
			&aon_dma 5 &aon_dma 6
			&aon_dma 7 &aon_dma 8
			&ap_dma 1 &ap_dma 2
			&ap_dma 3 &ap_dma 4>;
		dma-names = "da01-l", "da01-r", "da23-l", "da23-r",
			"normal-2stage-p", "normal-2stage-c",
			"deep-2stage-p", "ad23-2stage-c",
			"ad01-l", "ad01-r", "ad23-l", "ad23-r";
		/*
		 * bit map for dma-2stage-usecase
		 * bit[0] == 1, normal playback
		 * bit[1] ==1, deepbuf playback
		 * bit[2] ==1, caputre
		 * other bit to do
		 */
		sprd,dma-2stage-usecase = <2>;
		sprd,node-count-2stage-level-1 = <1>;
		sprd,syscon-pmu-apb = <&pmu_apb_controller>;
		/*
		 * 0: no interrupt, 1: from arm, 2:from ap
		 * note:if use arm ap should not register dma interrupt,
		 * and you should register intterupt in arm code.
		 */
		sprd,dma-2stage-level-1-int-source = <1>;
	};

	sprd_pcm_iis: sprd-pcm-iis {
		compatible = "sprd,pcm-platform-sharkl2";
		#sound-dai-cells = <0>;
		dmas = <&ap_dma 5 &ap_dma 6
			&ap_dma 7 &ap_dma 8
			&ap_dma 9 &ap_dma 10
			&ap_dma 11 &ap_dma 12>;
		dma-names = "iis0_tx", "iis0_rx",
			"iis1_tx", "iis1_rx",
			"iis2_tx", "iis2_rx",
			"iis3_tx", "iis3_rx";
		sprd,dma-2stage-usecase = <2>;
		sprd,node-count-2stage-level-1 = <1>;
		sprd,syscon-pmu-apb = <&pmu_apb_controller>;
		sprd,dma-2stage-level-1-int-source = <1>;
	};

	vaudio: vaudio {
		compatible = "sprd,vaudio";
		#sound-dai-cells = <1>;
	};

	saudio_lte{
		compatible = "sprd,saudio";
		sprd,saudio-dst-id = <5>;       /* SIPC_ID_LTE */
		sprd,ctrl_channel = <10>;       /* SMSG_CH_VBC */
		sprd,playback_channel = <11 131>; /* SMSG_CH_PLAYBACK */
		sprd,capture_channel = <12>;    /* SMSG_CH_CAPTURE */
		sprd,monitor_channel = <13>;    /*SMSG_CH_MONITOR_AUDIO */
		sprd,device = <2>;
		sprd,saudio-names = "saudiolte";
	};

	saudio_voip{
		compatible = "sprd,saudio";
		sprd,saudio-dst-id = <5>;       /* SIPC_ID_LTE */
		sprd,ctrl_channel = <14>;       /* SMSG_CH_CTRL_VOIP */
		sprd,playback_channel = <15 151>;/* SMSG_CH_PLAYBACK_VOIP */
		sprd,capture_channel = <16>;    /* SMSG_CH_CAPTURE_VOIP */
		sprd,monitor_channel = <17>;    /*SMSG_CH_MONITOR_VOIP */
		sprd,device = <2>;
		sprd,saudio-names = "saudiovoip";
	};

	audio-mem-mgr {
		compatible = "sprd,audio-mem-sharkl2";
		sprd,iram_phy_addr = <0x50010000 0xb000>;
		/* note:mmap address must paga_size align */
		sprd,iram_normal = <0x50010000 0x0>;
		sprd,iram_deepbuf = <0x50010000 0xa000>;
		sprd,iram_4arm7 = <0x5001a000 0x1000>;
	};

	deep-sleep {
		compatible = "sprd,deep-sleep";
		sprd,sys-ap-ahb = <&ap_ahb_controller>;
		sprd,sys-ap-apb = <&ap_apb_controller>;
		sprd,sys-pmu-apb = <&pmu_apb_controller>;
		sprd,sys-aon-apb = <&aon_apb_controller>;
		sprd,sys-anlg_phy_g1 = <&anlg_phy_g1_controller>;
		sprd,sys-anlg_phy_g2 = <&anlg_phy_g2_controller>;
		sprd,sys-anlg_phy_g3 = <&anlg_phy_g3_controller>;
		sprd,sys-anlg_phy_g4 = <&anlg_phy_g4_controller>;
		sprd,sys-anlg_phy_g5 = <&anlg_phy_g5_controller>;
		sprd,sys-aon-intc0 = <&aon_intc0_controller>;
		sprd,sys-aon-intc1 = <&aon_intc1_controller>;
		sprd,sys-aon-intc2 = <&aon_intc2_controller>;
		sprd,sys-aon-intc3 = <&aon_intc3_controller>;
		sprd,sys-aon-intc4 = <&aon_intc4_controller>;
		sprd,sys-aon-intc5 = <&aon_intc5_controller>;
		sprd,deep-ap-clk0 = <&clk_ap_apb
					&clk_uart0 &clk_uart1 &clk_uart2 &clk_uart3 &clk_uart4
					&clk_i2c0 &clk_i2c1 &clk_i2c2 &clk_i2c3 &clk_i2c4
					&clk_spi0 &clk_spi1 &clk_spi2
					&clk_iis0 &clk_iis1 &clk_iis2 &clk_iis3>;
		/*sprd,deep-ap-clk1 = <&clk_ap_usb3_ref>;*/
		sprd,deep-ap-clkp = <&ext_26m &ext_32k>;
	};

	sleep-ctrl {
		compatible = "sprd,sleep-ctrl";
		sprd,sys-pmu-apb = <&pmu_apb_controller>;
		sprd,pmu_reg = <0x00FC>;
		sprd,bit_mask = <0xFF>;
		sprd,bit_value = <0xFF>;
	};

	clk-default {
		compatible = "sprd,clk-default";
		sprd,syscon-pmu-apb = <&pmu_apb_controller>;
		sprd,syscon-aon-apb = <&aon_apb_controller>;
		pmu-pwd-list = <
			/* off    mask          value */
			0x1c	0x3000000	0x2000000
			0x20	0x3000000	0x2000000
			>;
		clock-names = "clk_gpu_eb", "clk_mm_eb";
		clocks = <&clk_aon_apb_gates0 27>, <&clk_aon_apb_gates0 25>;
	};
};
